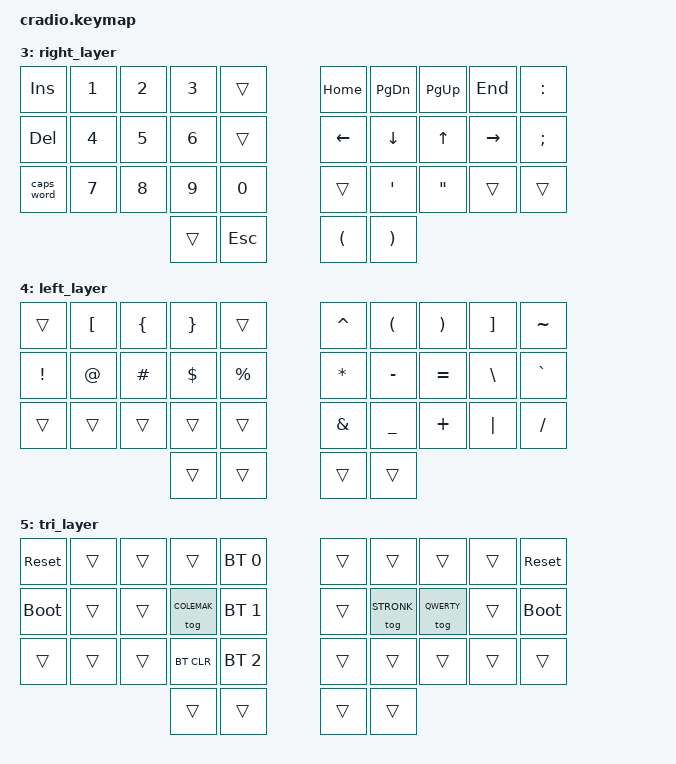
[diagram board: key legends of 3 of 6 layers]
// Copyright (c) 2022 The ZMK Contributors
// SPDX-License-Identifier: MIT

#include <behaviors.dtsi>
#include <dt-bindings/zmk/keys.h>
#include <dt-bindings/zmk/bt.h>

// Home row mods macro
#define HRML(k1,k2,k3,k4) &ht LGUI k1  &ht LALT k2  &ht LCTRL k3  &ht LSHFT k4
#define HRMR(k1,k2,k3,k4) &ht RSHFT k1  &ht RCTRL k2  &ht RALT k3  &ht RGUI k4

#define COLEMAK 0
#define STRONK 1
#define QWERTY 2
#define NUMBERS 3
#define SYMBOLS 4
#define DEBUG 5

/ {
    behaviors {
        ht: hold_tap {
            compatible = "zmk,behavior-hold-tap";
            #binding-cells = <2>;
            flavor = "tap-preferred";
            tapping-term-ms = <220>;
            quick-tap-ms = <150>;
            require-prior-idle-ms = <100>;
            bindings = <&kp>, <&kp>;
        };
    };

    conditional_layers {
        compatible = "zmk,conditional-layers";
        tri_layer {
            if-layers = <NUMBERS SYMBOLS>;
            then-layer = <DEBUG>;
        };
    };

    keymap {
        compatible = "zmk,keymap";
        default_layer {
            bindings = <
        //╭──────────┬──────────┬──────────┬──────────┬──────────╮   ╭──────────┬──────────┬──────────┬──────────┬──────────╮
        //│  Q       │  W       │  F       │  P       │  G       │   │  J       │  L       │  U       │  Y       │  :       │
            &kp Q      &kp W      &kp F      &kp P      &kp G          &kp J      &kp L      &kp U      &kp Y      &kp SEMI
        //├──────────┼──────────┼──────────┼──────────┼──────────┤   ├──────────┼──────────┼──────────┼──────────┼──────────┤
        //│  A       │  R       │  S       │  T       │  D       │   │  H       │  N       │  E       │  I       │ O      │
            HRML(A,        R,         S,         T)     &kp D          &kp H      HRMR(N,        E,         I,        O)
        //├──────────┼──────────┼──────────┼──────────┼──────────┤   ├──────────┼──────────┼──────────┼──────────┼──────────┤
        //│  Z       │  X       │  C       │  V       │  B       │   │  K       │  M       │ , <      │ . >      │ / ?      │
            &kp Z      &kp X      &kp C      &kp V      &kp B          &kp K      &kp M      &kp COMMA  &kp DOT    &kp FSLH
        //╰──────────┴──────────┴──────────┼──────────┼──────────┤   ├──────────┼──────────┼──────────┴──────────┴──────────╯
                                            &lt SYMBOLS TAB &kp ENTER   &kp SPACE  &lt NUMBERS BSPC
        //                                 ╰──────────┴──────────╯   ╰──────────┴──────────╯
            >;
        };
        fancy_layer {
            bindings = <
        //╭──────────┬──────────┬──────────┬──────────┬──────────╮   ╭──────────┬──────────┬──────────┬──────────┬──────────╮
        //│  F       │  D       │  L       │  B       │  V       │   │  J       │  G       │  O       │  U       │  , <       │
            &kp F      &kp D      &kp L      &kp B      &kp V          &kp J      &kp G      &kp O      &kp U      &kp COMMA
        //├──────────┼──────────┼──────────┼──────────┼──────────┤   ├──────────┼──────────┼──────────┼──────────┼──────────┤
        //│  S       │  T       │  R       │  N       │  K       │   │  Y       │  M       │  A       │  E       │   I      │
            HRML(S,        T,         R,         N)     &kp K          &kp Y      HRMR(M,        A,         E,        I)
        //├──────────┼──────────┼──────────┼──────────┼──────────┤   ├──────────┼──────────┼──────────┼──────────┼──────────┤
        //│  Z       │  Q       │  X       │  H       │  P       │   │  W       │  C       │ ' "      │ ; :      │ . >      │
            &kp Z      &kp Q      &kp X      &kp H      &kp P          &kp W      &kp C      &kp SQT   &kp SEMI    &kp DOT
        //╰──────────┴──────────┴──────────┼──────────┼──────────┤   ├──────────┼──────────┼──────────┴──────────┴──────────╯
                                            &lt SYMBOLS TAB   &kp ENTER       &kp SPACE  &lt NUMBERS BSPC
        //                                 ╰──────────┴──────────╯   ╰──────────┴──────────╯
            >;
        };
        qwerty {
            bindings = <
        //╭──────────┬──────────┬──────────┬──────────┬──────────╮   ╭──────────┬──────────┬──────────┬──────────┬──────────╮
        //│  Q       │  W       │  E       │  R       │  T       │   │  Y       │  U       │  I       │  O       │  P       │
            &kp Q      &kp W      &kp E      &kp R      &kp T          &kp Y      &kp U      &kp I      &kp O      &kp P
        //├──────────┼──────────┼──────────┼──────────┼──────────┤   ├──────────┼──────────┼──────────┼──────────┼──────────┤
        //│  A       │  S       │  D       │  F       │  G       │   │  H       │  J       │  K       │  L       │   ; :    │
            HRML(A,        S,         D,         F)     &kp G          &kp H      HRMR(J,        K,         L,        SEMI)
        //├──────────┼──────────┼──────────┼──────────┼──────────┤   ├──────────┼──────────┼──────────┼──────────┼──────────┤
        //│  Z       │  X       │  C       │  V       │  B       │   │  N       │  M       │ , <      │ . >      │ / ?      │
            &kp Z      &kp X      &kp C      &kp V      &kp B          &kp N      &kp M      &kp COMMA   &kp DOT    &kp FSLH
        //╰──────────┴──────────┴──────────┼──────────┼──────────┤   ├──────────┼──────────┼──────────┴──────────┴──────────╯
                                            &lt SYMBOLS TAB   &kp ENTER       &kp SPACE  &lt NUMBERS BSPC
        //                                 ╰──────────┴──────────╯   ╰──────────┴──────────╯
            >;
        };

        right_layer {
            bindings = <
        //╭──────────┬──────────┬──────────┬──────────┬──────────╮   ╭──────────┬──────────┬──────────┬──────────┬──────────╮
        //│ INSERT   │  1       │  2       │  3       │          │   │ HOME     │ PAGE DN  │ PAGE UP  │ END      │  :       │
            &kp INS    &kp N1     &kp N2     &kp N3     &trans         &kp HOME   &kp PG_DN  &kp PG_UP  &kp END    &kp COLON
        //├──────────┼──────────┼──────────┼──────────┼──────────┤   ├──────────┼──────────┼──────────┼──────────┼──────────┤
        //│ DELETE   │  4       │  5       │  6       │          │   │ LEFT     │ DOWN     │ UP       │ RIGHT    │  ;       │
            &kp DEL    &kp N4     &kp N5     &kp N6     &trans         &kp LEFT   &kp DOWN   &kp UP   &kp RIGHT   &kp SEMI
        //├──────────┼──────────┼──────────┼──────────┼──────────┤   ├──────────┼──────────┼──────────┼──────────┼──────────┤
        //│ CAPS     │  7       │  8       │  9       │  0       │   │          │ '        │   "      │          │          │
           &caps_word  &kp N7     &kp N8     &kp N9     &kp N0         &trans     &kp SQT     &kp DQT   &trans     &trans
        //╰──────────┴──────────┴──────────┼──────────┼──────────┤   ├──────────┼──────────┼──────────┴──────────┴──────────╯
                                             &trans     &kp ESC        &kp LPAR     &kp RPAR
        //                                 ╰──────────┴──────────╯   ╰──────────┴──────────╯
            >;
        };

        left_layer {
            bindings = <
        //╭──────────┬──────────┬──────────┬──────────┬──────────╮   ╭──────────┬──────────┬──────────┬──────────┬──────────╮
        //│          │  [       │  {       │  }       │          │   │  ^       │  (       │  )       │  ]       │  ~       │
            &trans     &kp LBKT   &kp LBRC   &kp RBRC   &trans         &kp CARET  &kp LPAR   &kp RPAR   &kp RBKT   &kp TILDE
        //├──────────┼──────────┼──────────┼──────────┼──────────┤   ├──────────┼──────────┼──────────┼──────────┼──────────┤
        //│  !       │  @       │  #       │  $       │  %       │   │  *       │  -       │  =       │  \       │  `       │
            &kp EXCL   &kp AT     &kp HASH   &kp DLLR   &kp PRCNT      &kp ASTRK  &kp MINUS  &kp EQUAL  &kp BSLH   &kp GRAVE
        //├──────────┼──────────┼──────────┼──────────┼──────────┤   ├──────────┼──────────┼──────────┼──────────┼──────────┤
        //│          │          │          │          │          │   │  &       │  _       │  +       │  │       │          │
            &trans     &trans     &trans     &trans     &trans         &kp AMPS   &kp UNDER  &kp PLUS   &kp PIPE   &kp FSLH
        //╰──────────┴──────────┴──────────┼──────────┼──────────┤   ├──────────┼──────────┼──────────┴──────────┴──────────╯
                                             &trans     &trans         &trans     &trans
        //                                 ╰──────────┴──────────╯   ╰──────────┴──────────╯
            >;
        };

        tri_layer {
            bindings = <
        //╭──────────┬──────────┬──────────┬──────────┬──────────╮   ╭──────────┬──────────┬──────────┬──────────┬──────────╮
        //│ RESET    │          │          │          │PROFILE 0 │   │          │          │          │          │  RESET   │
           &sys_reset  &trans     &trans     &trans    &bt BT_SEL 0    &trans     &trans     &trans     &trans    &sys_reset
        //├──────────┼──────────┼──────────┼──────────┼──────────┤   ├──────────┼──────────┼──────────┼──────────┼──────────┤
        //│BOOTLOADER│          │          │ COLEMAK  │PROFILE 1 │   │          │  STRONK  │  QWERTY  │          │BOOTLOADER│
          &bootloader  &trans     &trans     &tog COLEMAK &bt BT_SEL 1    &trans &tog STRONK &tog QWERTY     &trans    &bootloader
        //├──────────┼──────────┼──────────┼──────────┼──────────┤   ├──────────┼──────────┼──────────┼──────────┼──────────┤
        //│          │          │          │ CLEAR BT │PROFILE 2 │   │          │          │          │          │          │
            &trans     &trans     &trans    &bt BT_CLR &bt BT_SEL 2    &trans     &trans     &trans     &trans     &trans
        //╰──────────┴──────────┴──────────┼──────────┼──────────┤   ├──────────┼──────────┼──────────┴──────────┴──────────╯
                                             &trans     &trans         &trans     &trans
        //                                 ╰──────────┴──────────╯   ╰──────────┴──────────╯
            >;
        };
    };
};
